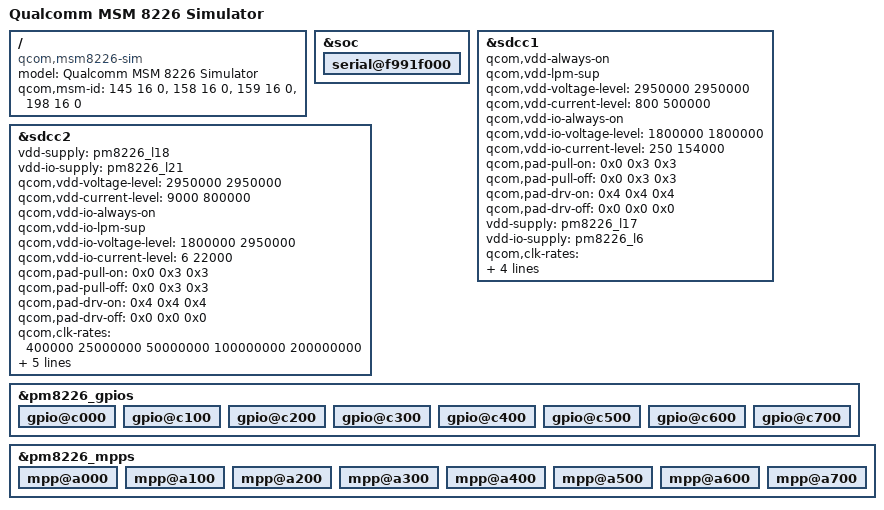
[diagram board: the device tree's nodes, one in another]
/* Copyright (c) 2012-2013, The Linux Foundation. All rights reserved.
 *
 * This program is free software; you can redistribute it and/or modify
 * it under the terms of the GNU General Public License version 2 and
 * only version 2 as published by the Free Software Foundation.
 *
 * This program is distributed in the hope that it will be useful,
 * but WITHOUT ANY WARRANTY; without even the implied warranty of
 * MERCHANTABILITY or FITNESS FOR A PARTICULAR PURPOSE.  See the
 * GNU General Public License for more details.
 */

/dts-v1/;
/include/ "msm8226.dtsi"

/ {
	model = "Qualcomm MSM 8226 Simulator";
	compatible = "qcom,msm8226-sim", "qcom,msm8226", "qcom,sim";
	qcom,msm-id = <145 16 0>,
		      <158 16 0>,
		      <159 16 0>,
		      <198 16 0>;
};

&soc {
	serial@f991f000 {
		status = "ok";
	};
};

&sdcc1 {
	qcom,vdd-always-on;
	qcom,vdd-lpm-sup;
	qcom,vdd-voltage-level = <2950000 2950000>;
	qcom,vdd-current-level = <800 500000>;

	qcom,vdd-io-always-on;
	qcom,vdd-io-voltage-level = <1800000 1800000>;
	qcom,vdd-io-current-level = <250 154000>;

	qcom,pad-pull-on = <0x0 0x3 0x3>; /* no-pull, pull-up, pull-up */
	qcom,pad-pull-off = <0x0 0x3 0x3>; /* no-pull, pull-up, pull-up */
	qcom,pad-drv-on = <0x4 0x4 0x4>; /* 10mA, 10mA, 10mA */
	qcom,pad-drv-off = <0x0 0x0 0x0>; /* 2mA, 2mA, 2mA */

	vdd-supply = <&pm8226_l17>;
	vdd-io-supply = <&pm8226_l6>;
	qcom,clk-rates = <400000 25000000 50000000 100000000 200000000>;
	qcom,sup-voltages = <2950 2950>;

	qcom,bus-speed-mode = "HS200_1p8v", "DDR_1p8v";
	qcom,nonremovable;
	status = "ok";
};

&sdcc2 {
	vdd-supply = <&pm8226_l18>;
	vdd-io-supply = <&pm8226_l21>;
	qcom,vdd-voltage-level = <2950000 2950000>;
	qcom,vdd-current-level = <9000 800000>;

	qcom,vdd-io-always-on;
	qcom,vdd-io-lpm-sup;
	qcom,vdd-io-voltage-level = <1800000 2950000>;
	qcom,vdd-io-current-level = <6 22000>;

	qcom,pad-pull-on = <0x0 0x3 0x3>; /* no-pull, pull-up, pull-up */
	qcom,pad-pull-off = <0x0 0x3 0x3>; /* no-pull, pull-up, pull-up */
	qcom,pad-drv-on = <0x4 0x4 0x4>; /* 10mA, 10mA, 10mA */
	qcom,pad-drv-off = <0x0 0x0 0x0>; /* 2mA, 2mA, 2mA */

	qcom,clk-rates = <400000 25000000 50000000 100000000 200000000>;
	qcom,sup-voltages = <2950 2950>;

	qcom,xpc;
	qcom,bus-speed-mode = "SDR12", "SDR25", "SDR50", "DDR50", "SDR104";
	qcom,current-limit = <800>;

	status = "ok";
};

&pm8226_gpios {
	gpio@c000 { /* GPIO 1 */
	};

	gpio@c100 { /* GPIO 2 */
	};

	gpio@c200 { /* GPIO 3 */
	};

	gpio@c300 { /* GPIO 4 */
	};

	gpio@c400 { /* GPIO 5 */
	};

	gpio@c500 { /* GPIO 6 */
	};

	gpio@c600 { /* GPIO 7 */
	};

	gpio@c700 { /* GPIO 8 */
	};
};

&pm8226_mpps {
	mpp@a000 { /* MPP 1 */
	};

	mpp@a100 { /* MPP 2 */
	};

	mpp@a200 { /* MPP 3 */
	};

	mpp@a300 { /* MPP 4 */
	};

	mpp@a400 { /* MPP 5 */
	};

	mpp@a500 { /* MPP 6 */
	};

	mpp@a600 { /* MPP 7 */
	};

	mpp@a700 { /* MPP 8 */
	};
};


